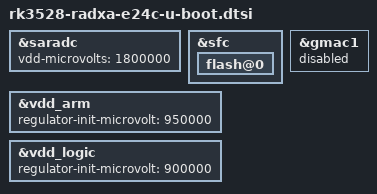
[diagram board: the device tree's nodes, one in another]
// SPDX-License-Identifier: (GPL-2.0+ OR MIT)

#include "rk3528-u-boot.dtsi"

&saradc {
	bootph-pre-ram;
	vdd-microvolts = <1800000>;
};

&sfc {
	flash@0 {
		bootph-pre-ram;
		bootph-some-ram;
	};
};

&vdd_arm {
	regulator-init-microvolt = <950000>;
};

&vdd_logic {
	regulator-init-microvolt = <900000>;
};

&gmac1 {
	status = "disabled"; // gmac works, but the dsa chip in front is not supported.
};
